# GAP8 register map
Vendor: GreenWaves Technologies SAS; Series: GAP8; File version: 1.3.1
GreenWaves GAP8 IoT Application Processor
CPU: other r1p0, little endian, MPU, no FPU, I-cache, DTCM, false interrupt priority bits
Registers are 32-bit, read-write, reset 0x0 unless marked. A register's access mark holds for its fields unless they carry their own. Offsets are from the block's base; lines under a group give offsets from that group; [hi:lo] are bit positions; {n}, {i} and the like mark numbered series; 'fields as' and 'values as' point back to an identical list; <NAME> marks a mode.

## Memory map
0x10200000 cl_ctrl size 0xCC — Cluster control unit
0x10200400 cl_timer_unit size 0x28 — Cluster timer
0x10200800 cl_event_unit size 0x704 — Cluster event unit
0x10201400 cl_icache_ctrl size 0x10 — Cluster instruction cache control unit
0x10201800 hwce size 0x288 — Hardware convolution engine
{0x10300000+0x8000*n} cl_core{n} size 0x7C54 (n=0..7) — Cluster Core {n} (Debug Unit)
0x1A100000 soc_fll size 0x10
0x1A100800 cluster_fll size 0x10
0x1A101000 apb_gpio size 0x40 — GPIO
0x1A102000 lvds size 0x44 — uDMA LVDS interface
0x1A102080 spim0 size 0x1C — SPI Master Channel 0
0x1A102100 spim1 size 0x1C — SPI Master Channel 1
0x1A102180 hyper size 0x48 — uDMA Hyperbus interface
0x1A102200 uart size 0x28 — uDMA UART interface
0x1A102280 i2c0 size 0x28 — I2C Channel 0
0x1A102300 i2c1 size 0x28 — I2C Channel 1
0x1A102380 memcpy size 0x2C — uDMA MEMCPY interface
0x1A102400 i2s size 0x38 — uDMA I2S interface
0x1A102480 cpi size 0x34 — uDMA CPI interface
0x1A102780 udma_ctrl size 0x8 — uDMA control unit
0x1A104000 apb_soc_ctrl size 0x1CC — SoC control unit
0x1A105000 apb_adv_timer size 0x108 — Advanced timer
0x1A106000 soc_event_generator size 0x2C
0x1A107000 dlc_bridge size 0x20 — PMU DLC bridge
0x1A108000 rtc size 0x18 — RealTime Counter
0x1A109000 efuse size 0x201
0x1B200000 fc_ctrl size 0x44 — FC control unit
0x1B200400 fc_timer_unit size 0x28 — FC timer
0x1B200800 fc_event_unit size 0x704
0x1B201400 fc_icache_ctrl size 0x10 — FC instruction cache control unit
0x1B300000 fc_core size 0x7C54 — FC Core 0 (Debug Unit)

## cl_ctrl — Cluster control unit
Base 0x10200000
0x00 eoc — End Of Computation status register.
  [0] eoc — End of computation status flag bitfield
    0=program execution under going; 1=end of computation reached
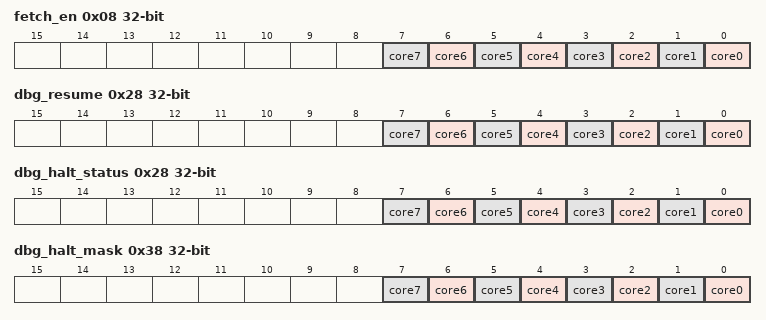
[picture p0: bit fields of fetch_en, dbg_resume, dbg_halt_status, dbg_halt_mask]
0x08 fetch_en — Cluster cores fetch enable configuration register.
  [all] fields
    0=disabled (feature is disabled); 1=enabled (feature is enabled)
  [n] core{n} (n=0..7) — Core {n} fetch enable configuration bitfield
0x20 clock_gate — Cluster clock gate configuration register.
  [0] en — Cluster clock gate configuration bitfield
    values as the fields of fetch_en
0x28 dbg_resume wo (alternate view of dbg_halt_status) — Cluster cores debug resume register.
  [n] core{n} (n=0..7) — Core {n} debug resume configuration bitfield
    on write: 0=stay_halted (set to stay halted); 1=resume_core_{n} (set to resume core {n})
0x28 dbg_halt_status ro (alternate view of dbg_resume) — Cluster cores debug halt status register.
  [all] fields
    on read: 0=running (feature is set to running); 1=halted (feature is set to halted)
  [n] core{n} (n=0..7) — Core {n} debug halt status flag bitfield
0x38 dbg_halt_mask — Cluster cores debug halt mask configuration register.
  [n] core{n} (n=0..7) — Core {n} debug halt mask bitfield. When bit is set, core will be part of mask group and stopped when one of the members of the group stops.
0x40 boot_addr0 — Cluster core 0 boot address configuration register.
  [31:0] ba — Cluster core 0 boot address configuration bitfield.
0x80 tcdm_arb_policy_ch0 — TCDM arbitration policy ch0 for cluster cores configuration register.
  [0] pol — TCDM arbitration policy for cluster cores configuration bitfield
    0=fair_round_robin (set to fair round robin); 1=fixed_order (set to fixed order)
0x88 tcdm_arb_policy_ch1 — TCDM arbitration policy ch1 for DMA/HWCE configuration register.
  [0] pol — TCDM arbitration policy for DMA/HWCE configuration bitfield
    values as tcdm_arb_policy_ch0.pol
0xC0 tcdm_arb_policy_ch0_rep — Read only duplicate of TCDM_ARB_POLICY_CH0 register
  fields as tcdm_arb_policy_ch0
0xC8 tcdm_arb_policy_ch1_rep — Read only duplicate of TCDM_ARB_POLICY_CH1 register
  fields as tcdm_arb_policy_ch1

## Licence text in the file
Copyright (c) 2017 GreenWaves Technologies SAS All rights reserved. Redistribution and use in source and binary forms, with or without modification, are permitted provided that the following conditions are met: 1. Redistributions of source code must retain the above copyright notice, this list of conditions and the following disclaimer. 2. Redistributions in binary form must reproduce the above copyright notice, this list of conditions and the following disclaimer in the documentation and/or other materials provided with the distribution. 3. Neither the name of GreenWaves Technologies SAS nor the names of its contributors may be used to endorse or promote products derived from this software without specific prior written permission. THIS SOFTWARE IS PROVIDED BY THE COPYRIGHT HOLDERS AND CONTRIBUTORS "AS IS" AND ANY EXPRESS OR IMPLIED WARRANTIES, INCLUDING, BUT NOT LIMITED TO, THE IMPLIED WARRANTIES OF MERCHANTABILITY AND FITNESS FOR A PARTICULAR PURPOSE ARE DISCLAIMED. IN NO EVENT SHALL THE COPYRIGHT OWNER OR CONTRIBUTORS BE LIABLE FOR ANY DIRECT, INDIRECT, INCIDENTAL, SPECIAL, EXEMPLARY, OR CONSEQUENTIAL DAMAGES (INCLUDING, BUT NOT LIMITED TO, PROCUREMENT OF SUBSTITUTE GOODS OR SERVICES; LOSS OF USE, DATA, OR PROFITS; OR BUSINESS INTERRUPTION) HOWEVER CAUSED AND ON ANY THEORY OF LIABILITY, WHETHER IN CONTRACT, STRICT LIABILITY, OR TORT (INCLUDING NEGLIGENCE OR OTHERWISE) ARISING IN ANY WAY OUT OF THE USE OF THIS SOFTWARE, EVEN IF ADVISED OF THE POSSIBILITY OF SUCH DAMAGE.
